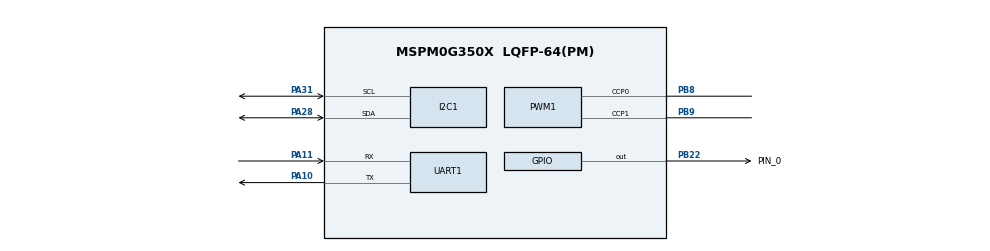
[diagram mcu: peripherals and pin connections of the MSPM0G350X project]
/**
 * @cliArgs --device "MSPM0G350X" --part "Default" --package "LQFP-64(PM)" --product "mspm0_sdk@2.10.00.04"
 * @versions {"tool":"1.26.2+4477"}
 */

/**
 * Import the modules used in this configuration.
 */
const GPIO   = scripting.addModule("/ti/driverlib/GPIO", {}, false);
const GPIO1  = GPIO.addInstance();
const I2C    = scripting.addModule("/ti/driverlib/I2C", {}, false);
const I2C1   = I2C.addInstance();
const PWM    = scripting.addModule("/ti/driverlib/PWM", {}, false);
const PWM1   = PWM.addInstance();
const SYSCTL = scripting.addModule("/ti/driverlib/SYSCTL");
const UART   = scripting.addModule("/ti/driverlib/UART", {}, false);
const UART1  = UART.addInstance();

/**
 * Write custom configuration values to the imported modules.
 */
GPIO1.$name                         = "GPIO_GRP_0";
GPIO1.associatedPins[0].$name       = "PIN_0";
GPIO1.associatedPins[0].pin.$assign = "PB22";

const Board = scripting.addModule("/ti/driverlib/Board", {}, false);

I2C1.$name                             = "I2C_OLED";
I2C1.basicEnableController             = true;
I2C1.peripheral.sdaPin.$assign         = "PA28";
I2C1.peripheral.sclPin.$assign         = "PA31";
I2C1.sdaPinConfig.$name                = "ti_driverlib_gpio_GPIOPinGeneric4";
I2C1.sdaPinConfig.hideOutputInversion  = scripting.forceWrite(false);
I2C1.sdaPinConfig.onlyInternalResistor = scripting.forceWrite(false);
I2C1.sdaPinConfig.passedPeripheralType = scripting.forceWrite("Digital");
I2C1.sclPinConfig.$name                = "ti_driverlib_gpio_GPIOPinGeneric5";
I2C1.sclPinConfig.hideOutputInversion  = scripting.forceWrite(false);
I2C1.sclPinConfig.onlyInternalResistor = scripting.forceWrite(false);
I2C1.sclPinConfig.passedPeripheralType = scripting.forceWrite("Digital");

PWM1.$name                      = "PWM_0";
PWM1.timerStartTimer            = true;
PWM1.timerCount                 = 10000;
PWM1.clockPrescale              = 64;
PWM1.peripheral.ccp0Pin.$assign = "PB8";
PWM1.peripheral.ccp1Pin.$assign = "PB9";
PWM1.PWM_CHANNEL_0.$name        = "ti_driverlib_pwm_PWMTimerCC0";
PWM1.PWM_CHANNEL_1.$name        = "ti_driverlib_pwm_PWMTimerCC1";
PWM1.ccp0PinConfig.$name        = "ti_driverlib_gpio_GPIOPinGeneric0";
PWM1.ccp1PinConfig.$name        = "ti_driverlib_gpio_GPIOPinGeneric1";

SYSCTL.forceDefaultClkConfig = true;
SYSCTL.clockTreeEn           = true;

UART1.$name                    = "UART_0";
UART1.targetBaudRate           = 115200;
UART1.peripheral.$assign       = "UART0";
UART1.peripheral.rxPin.$assign = "PA11";
UART1.peripheral.txPin.$assign = "PA10";
UART1.txPinConfig.$name        = "ti_driverlib_gpio_GPIOPinGeneric2";
UART1.rxPinConfig.$name        = "ti_driverlib_gpio_GPIOPinGeneric3";

/**
 * Pinmux solution for unlocked pins/peripherals. This ensures that minor changes to the automatic solver in a future
 * version of the tool will not impact the pinmux you originally saw.  These lines can be completely deleted in order to
 * re-solve from scratch.
 */
Board.peripheral.$suggestSolution          = "DEBUGSS";
Board.peripheral.swclkPin.$suggestSolution = "PA20";
Board.peripheral.swdioPin.$suggestSolution = "PA19";
I2C1.peripheral.$suggestSolution           = "I2C0";
PWM1.peripheral.$suggestSolution           = "TIMA0";
